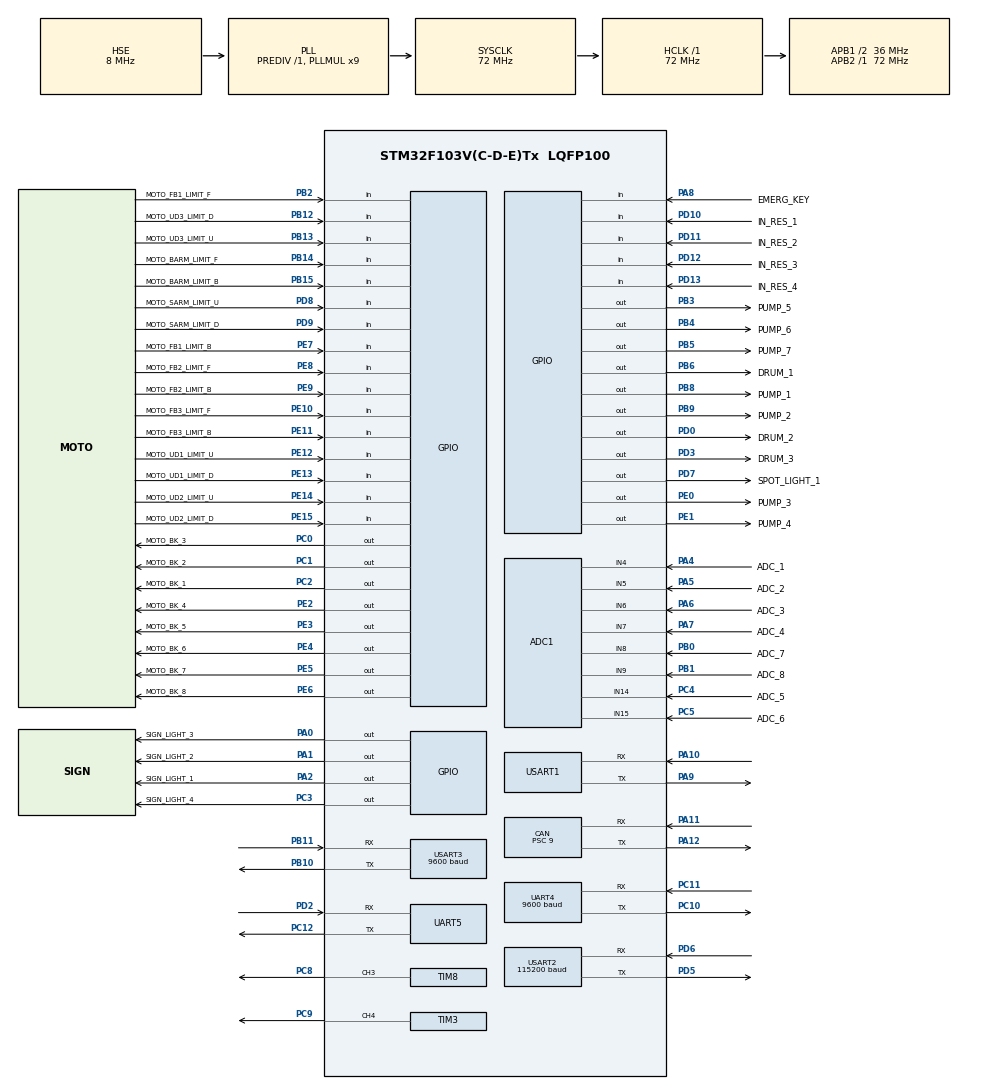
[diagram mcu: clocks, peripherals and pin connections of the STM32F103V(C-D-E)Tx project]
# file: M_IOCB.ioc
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ADC1.Channel-0\#ChannelRegularConversion=ADC_CHANNEL_4
ADC1.Channel-1\#ChannelRegularConversion=ADC_CHANNEL_5
ADC1.Channel-2\#ChannelRegularConversion=ADC_CHANNEL_6
ADC1.Channel-3\#ChannelRegularConversion=ADC_CHANNEL_7
ADC1.Channel-4\#ChannelRegularConversion=ADC_CHANNEL_14
ADC1.Channel-5\#ChannelRegularConversion=ADC_CHANNEL_15
ADC1.Channel-6\#ChannelRegularConversion=ADC_CHANNEL_8
ADC1.Channel-7\#ChannelRegularConversion=ADC_CHANNEL_9
ADC1.Channel-8\#ChannelRegularConversion=ADC_CHANNEL_VREFINT
ADC1.Channel-9\#ChannelRegularConversion=ADC_CHANNEL_TEMPSENSOR
ADC1.ContinuousConvMode=ENABLE
ADC1.DiscontinuousConvMode=DISABLE
ADC1.NbrOfConversion=10
ADC1.NbrOfConversionFlag=1
ADC1.Rank-0\#ChannelRegularConversion=1
ADC1.Rank-1\#ChannelRegularConversion=2
ADC1.Rank-2\#ChannelRegularConversion=3
ADC1.Rank-3\#ChannelRegularConversion=4
ADC1.Rank-4\#ChannelRegularConversion=5
ADC1.Rank-5\#ChannelRegularConversion=6
ADC1.Rank-6\#ChannelRegularConversion=7
ADC1.Rank-7\#ChannelRegularConversion=8
ADC1.Rank-8\#ChannelRegularConversion=9
ADC1.Rank-9\#ChannelRegularConversion=10
ADC1.SamplingTime-0\#ChannelRegularConversion=ADC_SAMPLETIME_1CYCLE_5
ADC1.SamplingTime-1\#ChannelRegularConversion=ADC_SAMPLETIME_1CYCLE_5
ADC1.SamplingTime-2\#ChannelRegularConversion=ADC_SAMPLETIME_1CYCLE_5
ADC1.SamplingTime-3\#ChannelRegularConversion=ADC_SAMPLETIME_1CYCLE_5
ADC1.SamplingTime-4\#ChannelRegularConversion=ADC_SAMPLETIME_1CYCLE_5
ADC1.SamplingTime-5\#ChannelRegularConversion=ADC_SAMPLETIME_1CYCLE_5
ADC1.SamplingTime-6\#ChannelRegularConversion=ADC_SAMPLETIME_1CYCLE_5
ADC1.SamplingTime-7\#ChannelRegularConversion=ADC_SAMPLETIME_1CYCLE_5
ADC1.SamplingTime-8\#ChannelRegularConversion=ADC_SAMPLETIME_1CYCLE_5
ADC1.SamplingTime-9\#ChannelRegularConversion=ADC_SAMPLETIME_1CYCLE_5
ADC1.master=1
CAN.BS1=CAN_BS1_5TQ
CAN.BS2=CAN_BS2_2TQ
CAN.CalculateBaudRate=500000
CAN.CalculateTimeBit=2000
CAN.CalculateTimeQuantum=250.0
CAN.Prescaler=9
CAN.SJW=CAN_SJW_1TQ
Dma.ADC1.2.Direction=DMA_PERIPH_TO_MEMORY
Dma.ADC1.2.Instance=DMA1_Channel1
Dma.ADC1.2.MemDataAlignment=DMA_MDATAALIGN_HALFWORD
Dma.ADC1.2.MemInc=DMA_MINC_ENABLE
Dma.ADC1.2.Mode=DMA_CIRCULAR
Dma.ADC1.2.PeriphDataAlignment=DMA_PDATAALIGN_HALFWORD
Dma.ADC1.2.PeriphInc=DMA_PINC_DISABLE
Dma.ADC1.2.Priority=DMA_PRIORITY_LOW
Dma.Request0=UART4_RX
Dma.Request1=USART1_RX
Dma.Request2=ADC1
Dma.Request3=TIM3_CH4/UP
Dma.Request4=TIM8_CH3/UP
Dma.TIM3_CH4/UP.3.Direction=DMA_MEMORY_TO_PERIPH
Dma.TIM3_CH4/UP.3.Instance=DMA1_Channel3
Dma.TIM3_CH4/UP.3.MemDataAlignment=DMA_MDATAALIGN_WORD
Dma.TIM3_CH4/UP.3.MemInc=DMA_MINC_ENABLE
Dma.TIM3_CH4/UP.3.Mode=DMA_NORMAL
Dma.TIM3_CH4/UP.3.PeriphDataAlignment=DMA_PDATAALIGN_WORD
Dma.TIM3_CH4/UP.3.PeriphInc=DMA_PINC_DISABLE
Dma.TIM3_CH4/UP.3.Priority=DMA_PRIORITY_LOW
Dma.TIM8_CH3/UP.4.Direction=DMA_PERIPH_TO_MEMORY
Dma.TIM8_CH3/UP.4.Instance=DMA2_Channel1
Dma.TIM8_CH3/UP.4.MemDataAlignment=DMA_MDATAALIGN_WORD
Dma.TIM8_CH3/UP.4.MemInc=DMA_MINC_ENABLE
Dma.TIM8_CH3/UP.4.Mode=DMA_NORMAL
Dma.TIM8_CH3/UP.4.PeriphDataAlignment=DMA_PDATAALIGN_WORD
Dma.TIM8_CH3/UP.4.PeriphInc=DMA_PINC_DISABLE
Dma.TIM8_CH3/UP.4.Priority=DMA_PRIORITY_LOW
Dma.UART4_RX.0.Direction=DMA_PERIPH_TO_MEMORY
Dma.UART4_RX.0.Instance=DMA2_Channel3
Dma.UART4_RX.0.MemDataAlignment=DMA_MDATAALIGN_BYTE
Dma.UART4_RX.0.MemInc=DMA_MINC_ENABLE
Dma.UART4_RX.0.Mode=DMA_NORMAL
Dma.UART4_RX.0.PeriphDataAlignment=DMA_PDATAALIGN_BYTE
Dma.UART4_RX.0.PeriphInc=DMA_PINC_DISABLE
Dma.UART4_RX.0.Priority=DMA_PRIORITY_LOW
Dma.USART1_RX.1.Direction=DMA_PERIPH_TO_MEMORY
Dma.USART1_RX.1.Instance=DMA1_Channel5
Dma.USART1_RX.1.MemDataAlignment=DMA_MDATAALIGN_BYTE
Dma.USART1_RX.1.MemInc=DMA_MINC_ENABLE
Dma.USART1_RX.1.Mode=DMA_NORMAL
Dma.USART1_RX.1.PeriphDataAlignment=DMA_PDATAALIGN_BYTE
Dma.USART1_RX.1.PeriphInc=DMA_PINC_DISABLE
Dma.USART1_RX.1.Priority=DMA_PRIORITY_LOW
FREERTOS.INCLUDE_uxTaskGetStackHighWaterMark=1
FREERTOS.Tasks01=defaultTask,0,300,StartDefaultTask,Default,NULL,Dynamic,NULL,NULL
FREERTOS.configGENERATE_RUN_TIME_STATS=0
FREERTOS.configTOTAL_HEAP_SIZE=30000
FREERTOS.configUSE_STATS_FORMATTING_FUNCTIONS=1
FREERTOS.configUSE_TRACE_FACILITY=1
Mcu.Family=STM32F1
Mcu.Name=STM32F103V(C-D-E)Tx
Mcu.Package=LQFP100
NVIC.CAN1_RX1_IRQn=true\:5\:0\:false\:false\:true\:true\:true\:true\:true
NVIC.CAN1_SCE_IRQn=true\:5\:0\:false\:false\:true\:true\:true\:true\:true
NVIC.DMA1_Channel1_IRQn=true\:5\:0\:false\:false\:true\:true\:true\:true\:true
NVIC.DMA1_Channel3_IRQn=true\:5\:0\:false\:false\:true\:true\:true\:true\:true
NVIC.DMA1_Channel5_IRQn=true\:5\:0\:false\:false\:true\:true\:true\:true\:true
NVIC.DMA2_Channel3_IRQn=true\:5\:0\:false\:false\:true\:true\:true\:true\:true
NVIC.PriorityGroup=NVIC_PRIORITYGROUP_4
NVIC.TIM7_IRQn=true\:15\:0\:false\:false\:true\:false\:false\:true\:true
NVIC.TimeBase=TIM7_IRQn
NVIC.TimeBaseIP=TIM7
NVIC.UART4_IRQn=true\:5\:0\:false\:false\:true\:true\:true\:true\:true
NVIC.UART5_IRQn=true\:5\:0\:false\:false\:true\:true\:true\:true\:true
NVIC.USART1_IRQn=true\:5\:0\:true\:false\:true\:true\:true\:true\:true
NVIC.USART2_IRQn=true\:5\:0\:false\:false\:true\:true\:true\:true\:true
NVIC.USART3_IRQn=true\:5\:0\:false\:false\:true\:true\:true\:true\:true
NVIC.USB_HP_CAN1_TX_IRQn=true\:5\:0\:false\:false\:true\:true\:true\:true\:true
NVIC.USB_LP_CAN1_RX0_IRQn=true\:5\:0\:false\:false\:true\:true\:true\:true\:true
OSC_IN.Mode=HSE-External-Oscillator
OSC_IN.Signal=RCC_OSC_IN
OSC_OUT.Mode=HSE-External-Oscillator
OSC_OUT.Signal=RCC_OSC_OUT
PA0-WKUP.GPIO_Label=SIGN_LIGHT_3
PA0-WKUP.GPIO_PuPd=GPIO_NOPULL
PA0-WKUP.Signal=GPIO_Output
PA1.GPIO_Label=SIGN_LIGHT_2
PA1.GPIO_PuPd=GPIO_NOPULL
PA1.Signal=GPIO_Output
PA10.Mode=Asynchronous
PA10.Signal=USART1_RX
PA11.Mode=CAN_Activate
PA11.Signal=CAN_RX
PA12.Mode=CAN_Activate
PA12.Signal=CAN_TX
PA13.Mode=Serial_Wire
PA13.Signal=SYS_JTMS-SWDIO
PA14.Mode=Serial_Wire
PA14.Signal=SYS_JTCK-SWCLK
PA2.GPIO_Label=SIGN_LIGHT_1
PA2.GPIO_PuPd=GPIO_NOPULL
PA2.Signal=GPIO_Output
PA4.GPIO_Label=ADC_1
PA4.Signal=ADCx_IN4
PA5.GPIO_Label=ADC_2
PA5.Signal=ADCx_IN5
PA6.GPIO_Label=ADC_3
PA6.Signal=ADCx_IN6
PA7.GPIO_Label=ADC_4
PA7.Signal=ADCx_IN7
PA8.GPIO_Label=EMERG_KEY
PA8.GPIO_PuPd=GPIO_PULLUP
PA8.Signal=GPIO_Input
PA9.Mode=Asynchronous
PA9.Signal=USART1_TX
PB0.GPIO_Label=ADC_7
PB0.Signal=ADCx_IN8
PB1.GPIO_Label=ADC_8
PB1.Signal=ADCx_IN9
PB10.Mode=Asynchronous
PB10.Signal=USART3_TX
PB11.Mode=Asynchronous
PB11.Signal=USART3_RX
PB12.GPIO_Label=MOTO_UD3_LIMIT_D
PB12.GPIO_PuPd=GPIO_PULLUP
PB12.Signal=GPIO_Input
PB13.GPIO_Label=MOTO_UD3_LIMIT_U
PB13.GPIO_PuPd=GPIO_PULLUP
PB13.Signal=GPIO_Input
PB14.GPIO_Label=MOTO_BARM_LIMIT_F
PB14.GPIO_PuPd=GPIO_PULLUP
PB14.Signal=GPIO_Input
PB15.GPIO_Label=MOTO_BARM_LIMIT_B
PB15.GPIO_PuPd=GPIO_PULLUP
PB15.Signal=GPIO_Input
PB2.GPIO_Label=MOTO_FB1_LIMIT_F
PB2.GPIO_PuPd=GPIO_PULLUP
PB2.Signal=GPIO_Input
PB3.GPIO_Label=PUMP_5
PB3.GPIO_Speed=GPIO_SPEED_FREQ_LOW
PB3.PinState=GPIO_PIN_RESET
PB3.Signal=GPIO_Output
PB4.GPIO_Label=PUMP_6
PB4.GPIO_Speed=GPIO_SPEED_FREQ_LOW
PB4.PinState=GPIO_PIN_RESET
PB4.Signal=GPIO_Output
PB5.GPIO_Label=PUMP_7
PB5.PinState=GPIO_PIN_RESET
PB5.Signal=GPIO_Output
PB6.GPIO_Label=DRUM_1
PB6.Signal=GPIO_Output
PB8.GPIO_Label=PUMP_1
PB8.GPIO_PuPd=GPIO_NOPULL
PB8.Signal=GPIO_Output
PB9.GPIO_Label=PUMP_2
PB9.GPIO_PuPd=GPIO_NOPULL
PB9.Signal=GPIO_Output
PC0.GPIO_Label=MOTO_BK_3
PC0.GPIO_PuPd=GPIO_NOPULL
PC0.Signal=GPIO_Output
PC1.GPIO_Label=MOTO_BK_2
PC1.GPIO_PuPd=GPIO_NOPULL
PC1.Signal=GPIO_Output
PC10.Mode=Asynchronous
PC10.Signal=UART4_TX
PC11.Mode=Asynchronous
PC11.Signal=UART4_RX
PC12.Mode=Asynchronous
PC12.Signal=UART5_TX
PC2.GPIO_Label=MOTO_BK_1
PC2.GPIO_PuPd=GPIO_NOPULL
PC2.Signal=GPIO_Output
PC3.GPIO_Label=SIGN_LIGHT_4
PC3.GPIO_PuPd=GPIO_NOPULL
PC3.Signal=GPIO_Output
PC4.GPIO_Label=ADC_5
PC4.Signal=ADCx_IN14
PC5.GPIO_Label=ADC_6
PC5.Signal=ADCx_IN15
PC8.Signal=S_TIM8_CH3
PC9.Signal=S_TIM3_CH4
PD0.GPIO_Label=DRUM_2
PD0.Signal=GPIO_Output
PD10.GPIO_Label=IN_RES_1
PD10.GPIO_PuPd=GPIO_PULLUP
PD10.Signal=GPIO_Input
PD11.GPIO_Label=IN_RES_2
PD11.GPIO_PuPd=GPIO_PULLUP
PD11.Signal=GPIO_Input
PD12.GPIO_Label=IN_RES_3
PD12.GPIO_PuPd=GPIO_PULLUP
PD12.Signal=GPIO_Input
PD13.GPIO_Label=IN_RES_4
PD13.GPIO_PuPd=GPIO_PULLUP
PD13.Signal=GPIO_Input
PD2.Mode=Asynchronous
PD2.Signal=UART5_RX
PD3.GPIO_Label=DRUM_3
PD3.Signal=GPIO_Output
PD5.Mode=Asynchronous
PD5.Signal=USART2_TX
PD6.Mode=Asynchronous
PD6.Signal=USART2_RX
PD7.GPIO_Label=SPOT_LIGHT_1
PD7.Signal=GPIO_Output
PD8.GPIO_Label=MOTO_SARM_LIMIT_U
PD8.GPIO_PuPd=GPIO_PULLUP
PD8.Signal=GPIO_Input
PD9.GPIO_Label=MOTO_SARM_LIMIT_D
PD9.GPIO_PuPd=GPIO_PULLUP
PD9.Signal=GPIO_Input
PE0.GPIO_Label=PUMP_3
PE0.GPIO_PuPd=GPIO_NOPULL
PE0.Signal=GPIO_Output
PE1.GPIO_Label=PUMP_4
PE1.GPIO_PuPd=GPIO_NOPULL
PE1.Signal=GPIO_Output
PE10.GPIO_Label=MOTO_FB3_LIMIT_F
PE10.GPIO_PuPd=GPIO_PULLUP
PE10.Signal=GPIO_Input
PE11.GPIO_Label=MOTO_FB3_LIMIT_B
PE11.GPIO_PuPd=GPIO_PULLUP
PE11.Signal=GPIO_Input
PE12.GPIO_Label=MOTO_UD1_LIMIT_U
PE12.GPIO_PuPd=GPIO_PULLUP
PE12.Signal=GPIO_Input
PE13.GPIO_Label=MOTO_UD1_LIMIT_D
PE13.GPIO_PuPd=GPIO_PULLUP
PE13.Signal=GPIO_Input
PE14.GPIO_Label=MOTO_UD2_LIMIT_U
PE14.GPIO_PuPd=GPIO_PULLUP
PE14.Signal=GPIO_Input
PE15.GPIO_Label=MOTO_UD2_LIMIT_D
PE15.GPIO_PuPd=GPIO_PULLUP
PE15.Signal=GPIO_Input
PE2.GPIO_Label=MOTO_BK_4
PE2.GPIO_PuPd=GPIO_NOPULL
PE2.Signal=GPIO_Output
PE3.GPIO_Label=MOTO_BK_5
PE3.GPIO_PuPd=GPIO_NOPULL
PE3.Signal=GPIO_Output
PE4.GPIO_Label=MOTO_BK_6
PE4.GPIO_PuPd=GPIO_NOPULL
PE4.Signal=GPIO_Output
PE5.GPIO_Label=MOTO_BK_7
PE5.GPIO_PuPd=GPIO_NOPULL
PE5.Signal=GPIO_Output
PE6.GPIO_Label=MOTO_BK_8
PE6.GPIO_PuPd=GPIO_NOPULL
PE6.Signal=GPIO_Output
PE7.GPIO_Label=MOTO_FB1_LIMIT_B
PE7.GPIO_PuPd=GPIO_PULLUP
PE7.Signal=GPIO_Input
PE8.GPIO_Label=MOTO_FB2_LIMIT_F
PE8.GPIO_PuPd=GPIO_PULLUP
PE8.Signal=GPIO_Input
PE9.GPIO_Label=MOTO_FB2_LIMIT_B
PE9.GPIO_PuPd=GPIO_PULLUP
PE9.Signal=GPIO_Input
ProjectManager.HeapSize=0x200
ProjectManager.StackSize=0x400
ProjectManager.TargetToolchain=MDK-ARM V5.32
RCC.ADCPresc=RCC_ADCPCLK2_DIV6
RCC.AHBFreq_Value=72000000
RCC.APB1CLKDivider=RCC_HCLK_DIV2
RCC.APB1Freq_Value=36000000
RCC.APB1TimFreq_Value=72000000
RCC.APB2Freq_Value=72000000
RCC.APB2TimFreq_Value=72000000
RCC.HCLKFreq_Value=72000000
RCC.PLLMUL=RCC_PLL_MUL9
RCC.PLLSourceVirtual=RCC_PLLSOURCE_HSE
RCC.SYSCLKFreq_VALUE=72000000
RCC.SYSCLKSource=RCC_SYSCLKSOURCE_PLLCLK
RCC.USBFreq_Value=72000000
RTC.Format=RTC_FORMAT_BIN
SH.ADCx_IN14.0=ADC1_IN14,IN14
SH.ADCx_IN15.0=ADC1_IN15,IN15
SH.ADCx_IN4.0=ADC1_IN4,IN4
SH.ADCx_IN5.0=ADC1_IN5,IN5
SH.ADCx_IN6.0=ADC1_IN6,IN6
SH.ADCx_IN7.0=ADC1_IN7,IN7
SH.ADCx_IN8.0=ADC1_IN8,IN8
SH.ADCx_IN9.0=ADC1_IN9,IN9
SH.S_TIM3_CH4.0=TIM3_CH4,PWM Generation4 CH4
SH.S_TIM8_CH3.0=TIM8_CH3,PWM Generation3 CH3
TIM3.Channel-PWM\ Generation4\ CH4=TIM_CHANNEL_4
TIM3.Period=89
TIM8.Channel-PWM\ Generation3\ CH3=TIM_CHANNEL_3
TIM8.Period=89
UART4.BaudRate=9600
UART4.VirtualMode=Asynchronous
UART5.VirtualMode=Asynchronous
USART1.VirtualMode=VM_ASYNC
USART2.BaudRate=115200
USART2.VirtualMode=VM_ASYNC
USART3.BaudRate=9600
USART3.VirtualMode=VM_ASYNC
VP_ADC1_TempSens_Input.Mode=IN-TempSens
VP_ADC1_Vref_Input.Mode=IN-Vrefint
VP_FREERTOS_VS_CMSIS_V1.Mode=CMSIS_V1
VP_RTC_VS_RTC_Activate.Mode=RTC_Enabled
VP_RTC_VS_RTC_Calendar.Mode=RTC_Calendar
VP_SYS_VS_tim7.Mode=TIM7
VP_TIM3_VS_ClockSourceINT.Mode=Internal
board=custom

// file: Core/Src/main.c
/* USER CODE BEGIN Header */
/**
 ******************************************************************************
 * @file           : main.c
 * @brief          : Main program body
 ******************************************************************************
 * @attention
 *
 * Copyright (c) 2023 STMicroelectronics.
 * All rights reserved.
 *
 * This software is licensed under terms that can be found in the LICENSE file
 * in the root directory of this software component.
 * If no LICENSE file comes with this software, it is provided AS-IS.
 *
 ******************************************************************************
 */
/* USER CODE END Header */
#include "main.h"
#include "cmsis_os.h"
#include "adc.h"
#include "can.h"
#include "dma.h"
#include "rtc.h"
#include "tim.h"
#include "usart.h"
#include "gpio.h"

/* USER CODE BEGIN Includes */
#include <stdio.h>
/* USER CODE END Includes */

void SystemClock_Config(void);
void MX_FREERTOS_Init(void);

int main(void)
{

  /* MCU Configuration--------------------------------------------------------*/

  /* Reset of all peripherals, Initializes the Flash interface and the Systick. */
  HAL_Init();

  /* Configure the system clock */
  SystemClock_Config();

  /* Initialize all configured peripherals */
  MX_GPIO_Init();
  MX_DMA_Init();
  MX_RTC_Init();
  MX_USART1_UART_Init();
  MX_UART4_Init();
  MX_UART5_Init();
  MX_USART2_UART_Init();
  MX_USART3_UART_Init();
  MX_ADC1_Init();
  MX_CAN_Init();
  MX_TIM3_Init();
  MX_TIM8_Init();

  /* Call init function for freertos objects (in freertos.c) */
  MX_FREERTOS_Init();

  /* Start scheduler */
  osKernelStart();

  /* We should never get here as control is now taken by the scheduler */
  /* Infinite loop */
  while (1)
  {

  }
}

void SystemClock_Config(void)
{
  RCC_OscInitTypeDef RCC_OscInitStruct = {0};
  RCC_ClkInitTypeDef RCC_ClkInitStruct = {0};
  RCC_PeriphCLKInitTypeDef PeriphClkInit = {0};

  /** Initializes the RCC Oscillators according to the specified parameters
  * in the RCC_OscInitTypeDef structure.
  */
  RCC_OscInitStruct.OscillatorType = RCC_OSCILLATORTYPE_LSI|RCC_OSCILLATORTYPE_HSE;
  RCC_OscInitStruct.HSEState = RCC_HSE_ON;
  RCC_OscInitStruct.HSEPredivValue = RCC_HSE_PREDIV_DIV1;
  RCC_OscInitStruct.HSIState = RCC_HSI_ON;
  RCC_OscInitStruct.LSIState = RCC_LSI_ON;
  RCC_OscInitStruct.PLL.PLLState = RCC_PLL_ON;
  RCC_OscInitStruct.PLL.PLLSource = RCC_PLLSOURCE_HSE;
  RCC_OscInitStruct.PLL.PLLMUL = RCC_PLL_MUL9;
  if (HAL_RCC_OscConfig(&RCC_OscInitStruct) != HAL_OK)
  {
    Error_Handler();
  }

  /** Initializes the CPU, AHB and APB buses clocks
  */
  RCC_ClkInitStruct.ClockType = RCC_CLOCKTYPE_HCLK|RCC_CLOCKTYPE_SYSCLK
                              |RCC_CLOCKTYPE_PCLK1|RCC_CLOCKTYPE_PCLK2;
  RCC_ClkInitStruct.SYSCLKSource = RCC_SYSCLKSOURCE_PLLCLK;
  RCC_ClkInitStruct.AHBCLKDivider = RCC_SYSCLK_DIV1;
  RCC_ClkInitStruct.APB1CLKDivider = RCC_HCLK_DIV2;
  RCC_ClkInitStruct.APB2CLKDivider = RCC_HCLK_DIV1;

  if (HAL_RCC_ClockConfig(&RCC_ClkInitStruct, FLASH_LATENCY_2) != HAL_OK)
  {
    Error_Handler();
  }
  PeriphClkInit.PeriphClockSelection = RCC_PERIPHCLK_RTC|RCC_PERIPHCLK_ADC;
  PeriphClkInit.RTCClockSelection = RCC_RTCCLKSOURCE_LSI;
  PeriphClkInit.AdcClockSelection = RCC_ADCPCLK2_DIV6;
  if (HAL_RCCEx_PeriphCLKConfig(&PeriphClkInit) != HAL_OK)
  {
    Error_Handler();
  }
}

/* USER CODE BEGIN 4 */
int fputc(int ch, FILE *f)
{
  HAL_UART_Transmit(&huart1, (uint8_t *)&ch, 1, 0xFFFF);
  return ch;
}

/* USER CODE END 4 */

void HAL_TIM_PeriodElapsedCallback(TIM_HandleTypeDef *htim)
{
  if (htim->Instance == TIM7) {
    HAL_IncTick();
  }
}

void Error_Handler(void)
{
  __disable_irq();
  while (1)
  {
  }
}

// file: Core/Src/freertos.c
/* USER CODE BEGIN Header */
/**
 ******************************************************************************
 * File Name          : freertos.c
 * Description        : Code for freertos applications
 ******************************************************************************
 * @attention
 *
 * Copyright (c) 2023 STMicroelectronics.
 * All rights reserved.
 *
 * This software is licensed under terms that can be found in the LICENSE file
 * in the root directory of this software component.
 * If no LICENSE file comes with this software, it is provided AS-IS.
 *
 ******************************************************************************
 */
/* USER CODE END Header */

#include "FreeRTOS.h"
#include "task.h"
#include "main.h"
#include "cmsis_os.h"

/* USER CODE BEGIN Includes */
#include "stdio.h"
#include "motor_drive.h"
#include "can.h"
#include "adc.h"
#include "usart.h"
#include "elog.h"
#include "flashdb.h"
#include "tim.h"
#include "console.h"
#include "ws2812.h"
#include "liquid_level.h"
#include "hcp.h"
#include "brush.h"
#include "flowmeter_hl.h"
// #include "battery.h"
/* USER CODE END Includes */

/* USER CODE BEGIN PD */

TaskHandle_t test_task_handle;
extern TaskHandle_t console_task_handle;
extern TaskHandle_t motor_task_handle;
extern TaskHandle_t rgb_task_handle;
extern TaskHandle_t liquid_level_task_handle;
extern TaskHandle_t hcp_task_handle;
extern TaskHandle_t brush_deamon_task_handle;
extern TaskHandle_t flowmeter_task_handle;
extern TaskHandle_t battery_task_handle;
extern TaskHandle_t accurate_ratio_task_handle;

void test_task(void);

unsigned char u1_rec_buf[100];

// static uint32_t boot_count = 0;
// struct fdb_default_kv default_kv;
// static struct fdb_kvdb kvdb = {0};
// static struct fdb_default_kv_node default_kv_table[] = {
//     {"boot_count", &boot_count, sizeof(boot_count)}, /* int type KV */
// };

unsigned char pb_bat_level = 0;
unsigned char pb_charge_state = 0;
unsigned char pb_rec_buf[5] = {0};
unsigned char pb_rec = 0;
/* USER CODE END PD */

osThreadId defaultTaskHandle;

/* USER CODE BEGIN FunctionPrototypes */
void cs_task_manager_cb(unsigned char *cmd);
void cs_task_HighWaterMark_cb(unsigned char *cmd);
/* USER CODE END FunctionPrototypes */

void StartDefaultTask(void const *argument);

void MX_FREERTOS_Init(void); /* (MISRA C 2004 rule 8.1) */

/* GetIdleTaskMemory prototype (linked to static allocation support) */
void vApplicationGetIdleTaskMemory(StaticTask_t **ppxIdleTaskTCBBuffer, StackType_t **ppxIdleTaskStackBuffer, uint32_t *pulIdleTaskStackSize);

/* USER CODE BEGIN GET_IDLE_TASK_MEMORY */
static StaticTask_t xIdleTaskTCBBuffer;
static StackType_t xIdleStack[configMINIMAL_STACK_SIZE];

void vApplicationGetIdleTaskMemory(StaticTask_t **ppxIdleTaskTCBBuffer, StackType_t **ppxIdleTaskStackBuffer, uint32_t *pulIdleTaskStackSize)
{
  *ppxIdleTaskTCBBuffer = &xIdleTaskTCBBuffer;
  *ppxIdleTaskStackBuffer = &xIdleStack[0];
  *pulIdleTaskStackSize = configMINIMAL_STACK_SIZE;
  /* place for user code */
}
/* USER CODE END GET_IDLE_TASK_MEMORY */

void MX_FREERTOS_Init(void)
{
  /* USER CODE BEGIN Init */
  // default_kv.kvs = default_kv_table;
  // default_kv.num = sizeof(default_kv_table) / sizeof(default_kv_table[0]);
  // fdb_kvdb_init(&kvdb, "NVS", "fdb", &default_kv, NULL);
  elog_my_init();
  cs_init();
  HAL_UART_Receive_IT(&huart5, &pb_rec, 1);
  // cs_recv_start();
  /* USER CODE END Init */

  /* Create the thread(s) */
  /* definition and creation of defaultTask */
  osThreadDef(defaultTask, StartDefaultTask, osPriorityNormal, 0, 300);
  defaultTaskHandle = osThreadCreate(osThread(defaultTask), NULL);

  /* USER CODE BEGIN RTOS_THREADS */
  /* add threads, ... */
  xTaskCreate((TaskFunction_t)console_task, "console_task", 600, NULL, 0, &console_task_handle);
  xTaskCreate((TaskFunction_t)hcp_task, "hcp task", 600, NULL, 5, &hcp_task_handle);
  // xTaskCreate((TaskFunction_t)test_task, "test_task", 400, NULL, 0, &test_task_handle);
  xTaskCreate((TaskFunction_t)motor_task, "motor_task", 400, NULL, 0, &motor_task_handle);
  // xTaskCreate((TaskFunction_t)rgb_task, "rgb_task", 100, NULL, 2, &rgb_task_handle);
  xTaskCreate((TaskFunction_t)liquid_level_task, "liquid level task", 100, NULL, 0, &liquid_level_task_handle);
  xTaskCreate((TaskFunction_t)brush_deamon_task, "brush deamon task", 400, NULL, 4, &brush_deamon_task_handle);
  xTaskCreate((TaskFunction_t)flowmeter_task, "flowmeter task", 200, NULL, 1, &flowmeter_task_handle);
  // xTaskCreate((TaskFunction_t)battery_task, "battery task", 200, NULL, 1, &battery_task_handle);
  xTaskCreate((TaskFunction_t)accurate_ratio_task, "accurate ratio task", 200, NULL, 1, &accurate_ratio_task_handle);
  /* USER CODE END RTOS_THREADS */
}

void StartDefaultTask(void const *argument)
{
  /* USER CODE BEGIN StartDefaultTask */
  /* Infinite loop */

  // struct fdb_blob blob;
  // int boot_count = 0;

  // printf("\r==================== kvdb_basic_sample ====================\r\n");
  // { /* GET the KV value */
  //   /* get the "boot_count" KV value */
  //   fdb_kv_get_blob(&kvdb, "boot_count", fdb_blob_make(&blob, &boot_count, sizeof(boot_count)));
  //   /* the blob.saved.len is more than 0 when get the value successful */
  //   if (blob.saved.len > 0)
  //   {
  //     printf("get the 'boot_count' value is %d\r\n", boot_count);
  //   }
  //   else
  //   {
  //     printf("get the 'boot_count' failed\r\n");
  //   }
  // }
  // { /* CHANGE the KV value */
  //   /* increase the boot count */
  //   boot_count++;
  //   /* change the "boot_count" KV's value */
  //   fdb_kv_set_blob(&kvdb, "boot_count", fdb_blob_make(&blob, &boot_count, sizeof(boot_count)));
  //   // printf("set the 'boot_count' value to %d\n", boot_count);
  // }
  // printf("===========================================================\r\n");

  cs_reg_fun("info", cs_task_HighWaterMark_cb);
  cs_reg_fun("sys", cs_task_manager_cb);
  // MOTOR_BK_ON[0]();
  // MOTOR_BK_ON[1]();
  // MOTOR_BK_ON[2]();
  // MOTOR_BK_ON[3]();
  // MOTOR_BK_ON[4]();
  // MOTOR_BK_ON[5]();
  // MOTOR_BK_ON[6]();
  // MOTOR_BK_ON[7]();

  // vTaskDelete(NULL);
  // char bat = 0;
  vTaskDelay(6000 / portTICK_RATE_MS);
  for (;;)
  {
    // bat_get_power(&bat);
    // printf("%d", bat);
    osDelay(200);

    // elog_i("speed", "%d#%ld", motor_read_speed(MOTOR_STATION[MOTOR_UD_2]), motor_read_position(MOTOR_STATION[MOTOR_UD_2]));
    // printf("%d-%d-%d-%d-%d-%d-%d-%d-%d-%d-%d-%d-%d-%d-%d-%d\r\n",
    //    HAL_GPIO_ReadPin(MOTO_FB1_LIMIT_F_GPIO_Port, MOTO_FB1_LIMIT_F_Pin),
    //    HAL_GPIO_ReadPin(MOTO_FB1_LIMIT_B_GPIO_Port, MOTO_FB1_LIMIT_B_Pin),
    //    HAL_GPIO_ReadPin(MOTO_FB2_LIMIT_F_GPIO_Port, MOTO_FB2_LIMIT_F_Pin),
    //    HAL_GPIO_ReadPin(MOTO_FB2_LIMIT_B_GPIO_Port, MOTO_FB2_LIMIT_B_Pin),
    //    HAL_GPIO_ReadPin(MOTO_FB3_LIMIT_F_GPIO_Port, MOTO_FB3_LIMIT_F_Pin),
    //    HAL_GPIO_ReadPin(MOTO_FB3_LIMIT_B_GPIO_Port, MOTO_FB3_LIMIT_B_Pin),
    //    HAL_GPIO_ReadPin(MOTO_UD1_LIMIT_U_GPIO_Port, MOTO_UD1_LIMIT_U_Pin),
    //    HAL_GPIO_ReadPin(MOTO_UD1_LIMIT_D_GPIO_Port, MOTO_UD1_LIMIT_D_Pin),
    //    HAL_GPIO_ReadPin(MOTO_UD2_LIMIT_U_GPIO_Port, MOTO_UD2_LIMIT_U_Pin),
    //    HAL_GPIO_ReadPin(MOTO_UD2_LIMIT_D_GPIO_Port, MOTO_UD2_LIMIT_D_Pin),
    //    HAL_GPIO_ReadPin(MOTO_UD3_LIMIT_D_GPIO_Port, MOTO_UD3_LIMIT_D_Pin),
    //    HAL_GPIO_ReadPin(MOTO_UD3_LIMIT_U_GPIO_Port, MOTO_UD3_LIMIT_U_Pin),
    //    HAL_GPIO_ReadPin(MOTO_BARM_LIMIT_F_GPIO_Port, MOTO_BARM_LIMIT_F_Pin),
    //    HAL_GPIO_ReadPin(MOTO_BARM_LIMIT_B_GPIO_Port, MOTO_BARM_LIMIT_B_Pin),
    //    HAL_GPIO_ReadPin(MOTO_SARM_LIMIT_U_GPIO_Port, MOTO_SARM_LIMIT_U_Pin),
    //    HAL_GPIO_ReadPin(MOTO_SARM_LIMIT_D_GPIO_Port, MOTO_SARM_LIMIT_D_Pin));

    // HAL_GPIO_TogglePin(OU_RES_4_GPIO_Port, OU_RES_4_Pin);
    // HAL_GPIO_TogglePin(OU_RES_5_GPIO_Port, OU_RES_5_Pin);
  }
  /* USER CODE END StartDefaultTask */
}

/* USER CODE BEGIN Application */

void test_task()
{

  // char send_buf[25];
  // unsigned int liquid_level_1 = 0;
  // unsigned int liquid_level_2 = 0;
  // unsigned int liquid_level_3 = 0;
  // unsigned int liquid_level_4 = 0;
  // rgb_test_fun();
  // HAL_TIM_PWM_Start(&htim3,TIM_CHANNEL_4);
  // __HAL_TIM_SetCompare(&htim3, TIM_CHANNEL_4, 20);

  while (1)
  {
    // get_liquid_level(&liquid_level_1, &liquid_level_2, &liquid_level_3, &liquid_level_4);
    // sprintf(send_buf, "%d,%d,%d,%d\r\n", liquid_level_1, liquid_level_2, liquid_level_3, liquid_level_4);
    // printf("%s", send_buf);

    // HAL_GPIO_TogglePin(SIGN_LIGHT_1_GPIO_Port, SIGN_LIGHT_1_Pin);
    // vTaskDelay(50 / portTICK_RATE_MS);
    // HAL_GPIO_TogglePin(SIGN_LIGHT_2_GPIO_Port, SIGN_LIGHT_2_Pin);
    // vTaskDelay(50 / portTICK_RATE_MS);
    // HAL_GPIO_TogglePin(SIGN_LIGHT_3_GPIO_Port, SIGN_LIGHT_3_Pin);
    // vTaskDelay(50 / portTICK_RATE_MS);
    // HAL_GPIO_TogglePin(SIGN_LIGHT_4_GPIO_Port, SIGN_LIGHT_4_Pin);
    // vTaskDelay(50 / portTICK_RATE_MS);
    // HAL_GPIO_TogglePin(MOTO_BK_1_GPIO_Port, MOTO_BK_1_Pin);
    // vTaskDelay(50 / portTICK_RATE_MS);
    // HAL_GPIO_TogglePin(MOTO_BK_2_GPIO_Port, MOTO_BK_2_Pin);
    // vTaskDelay(50 / portTICK_RATE_MS);
    // HAL_GPIO_TogglePin(MOTO_BK_3_GPIO_Port, MOTO_BK_3_Pin);
    // vTaskDelay(50 / portTICK_RATE_MS);
    // HAL_GPIO_TogglePin(MOTO_BK_4_GPIO_Port, MOTO_BK_4_Pin);
    // vTaskDelay(50 / portTICK_RATE_MS);
    // HAL_GPIO_TogglePin(MOTO_BK_5_GPIO_Port, MOTO_BK_5_Pin);
    // vTaskDelay(50 / portTICK_RATE_MS);
    // HAL_GPIO_TogglePin(MOTO_BK_6_GPIO_Port, MOTO_BK_6_Pin);
    // vTaskDelay(50 / portTICK_RATE_MS);
    // HAL_GPIO_TogglePin(MOTO_BK_7_GPIO_Port, MOTO_BK_7_Pin);
    // vTaskDelay(50 / portTICK_RATE_MS);
    // HAL_GPIO_TogglePin(MOTO_BK_8_GPIO_Port, MOTO_BK_8_Pin);

    // vTaskDelay(50 / portTICK_RATE_MS);
    // HAL_GPIO_TogglePin(PUMP_1_GPIO_Port, PUMP_1_Pin);
    // vTaskDelay(50 / portTICK_RATE_MS);
    // HAL_GPIO_TogglePin(PUMP_2_GPIO_Port, PUMP_2_Pin);
    // vTaskDelay(50 / portTICK_RATE_MS);
    // HAL_GPIO_TogglePin(PUMP_3_GPIO_Port, PUMP_3_Pin);
    // vTaskDelay(50 / portTICK_RATE_MS);
    // HAL_GPIO_TogglePin(PUMP_4_GPIO_Port, PUMP_4_Pin);
    // vTaskDelay(50 / portTICK_RATE_MS);

    // HAL_GPIO_TogglePin(DRUM_1_GPIO_Port, DRUM_1_Pin);
    // vTaskDelay(50 / portTICK_RATE_MS);
    // HAL_GPIO_TogglePin(DRUM_2_GPIO_Port, DRUM_2_Pin);
    // vTaskDelay(50 / portTICK_RATE_MS);
    // HAL_GPIO_TogglePin(DRUM_3_GPIO_Port, DRUM_3_Pin);
    // vTaskDelay(50 / portTICK_RATE_MS);

    // HAL_GPIO_TogglePin(SPOT_LIGHT_1_GPIO_Port, SPOT_LIGHT_1_Pin);
    // vTaskDelay(50 / portTICK_RATE_MS);
    // HAL_GPIO_TogglePin(SPOT_LIGHT_2_GPIO_Port, SPOT_LIGHT_2_Pin);
    // vTaskDelay(50 / portTICK_RATE_MS);

    // HAL_UART_Transmit(&huart2, "hello\r\n", 7, 1000);
    vTaskDelay(500 / portTICK_RATE_MS);
    printf("%d-%d-%d-%d-%d-%d-%d-%d-%d-%d-%d-%d-%d-%d-%d-%d\r\n",
           HAL_GPIO_ReadPin(MOTO_FB1_LIMIT_F_GPIO_Port, MOTO_FB1_LIMIT_F_Pin),
           HAL_GPIO_ReadPin(MOTO_FB1_LIMIT_B_GPIO_Port, MOTO_FB1_LIMIT_B_Pin),
           HAL_GPIO_ReadPin(MOTO_FB2_LIMIT_F_GPIO_Port, MOTO_FB2_LIMIT_F_Pin),
           HAL_GPIO_ReadPin(MOTO_FB2_LIMIT_B_GPIO_Port, MOTO_FB2_LIMIT_B_Pin),
           HAL_GPIO_ReadPin(MOTO_FB3_LIMIT_F_GPIO_Port, MOTO_FB3_LIMIT_F_Pin),
           HAL_GPIO_ReadPin(MOTO_FB3_LIMIT_B_GPIO_Port, MOTO_FB3_LIMIT_B_Pin),
           HAL_GPIO_ReadPin(MOTO_UD1_LIMIT_U_GPIO_Port, MOTO_UD1_LIMIT_U_Pin),
           HAL_GPIO_ReadPin(MOTO_UD1_LIMIT_D_GPIO_Port, MOTO_UD1_LIMIT_D_Pin),
           HAL_GPIO_ReadPin(MOTO_UD2_LIMIT_U_GPIO_Port, MOTO_UD2_LIMIT_U_Pin),
           HAL_GPIO_ReadPin(MOTO_UD2_LIMIT_D_GPIO_Port, MOTO_UD2_LIMIT_D_Pin),
           HAL_GPIO_ReadPin(MOTO_UD3_LIMIT_U_GPIO_Port, MOTO_UD3_LIMIT_U_Pin),
           HAL_GPIO_ReadPin(MOTO_UD3_LIMIT_D_GPIO_Port, MOTO_UD3_LIMIT_D_Pin),
           HAL_GPIO_ReadPin(MOTO_BARM_LIMIT_F_GPIO_Port, MOTO_BARM_LIMIT_F_Pin),
           HAL_GPIO_ReadPin(MOTO_BARM_LIMIT_B_GPIO_Port, MOTO_BARM_LIMIT_B_Pin),
           HAL_GPIO_ReadPin(MOTO_SARM_LIMIT_U_GPIO_Port, MOTO_SARM_LIMIT_U_Pin),
           HAL_GPIO_ReadPin(MOTO_SARM_LIMIT_D_GPIO_Port, MOTO_SARM_LIMIT_D_Pin));
  }
}

void HAL_UARTEx_RxEventCallback(UART_HandleTypeDef *huart, uint16_t Size)
{
  // Log serial port
  if (huart == &huart1)
  {
    cs_recv_callback(Size);
  }
  else if (huart == &huart4)
  {
    fm_recv_callback(Size);
  }
  // 232 serial port of upper computer
  // else if (huart == &huart2)
  // {
  //   hcp_recv_callback(Size);
  // }
  // power
  // else if (huart == &huart3)
  // {
  //   bat_recv_callback(Size);
  // }
}

extern unsigned char hcp_buf[40];
extern unsigned char hcp_rec_s;
void HAL_UART_RxCpltCallback(UART_HandleTypeDef *huart)
{
  static unsigned char pb_rec_buf[5] = {0};
  static unsigned char pb_rec_index = 0;
  static unsigned int hcp_rec_index = 0;

  if (huart == &huart5)
  {
    if (pb_rec == 0x5a)
    {
      pb_rec_index = 0;
    }
    pb_rec_buf[pb_rec_index++] = pb_rec;
    if (pb_rec_index > 3)
    {
      if (pb_rec == 0xa5)
      {
        pb_bat_level = pb_rec_buf[1];
        pb_charge_state = pb_rec_buf[2];
        // printf("%d-%d\r\n", pb_bat_level, pb_charge_state);
      }
      pb_rec_index = 0;
    }
    HAL_UART_Receive_IT(&huart5, &pb_rec, 1);
  }
  else if (huart == &huart2)
  {
    if (hcp_rec_s == 0x5a)
    {
      if (hcp_buf[0] != 0x5a)
      {
        hcp_rec_index = 0;
      }
    }
    hcp_buf[hcp_rec_index++] = hcp_rec_s;
    if (hcp_rec_index > 15)
    {
      hcp_recv_callback(hcp_rec_index);
      hcp_rec_index = 0;
    }
    else
    {
      HAL_UART_Receive_IT(&huart2, &hcp_rec_s, 1);
    }
  }
}

void cs_task_manager_cb(unsigned char *cmd)
{
  unsigned char write_buffer[500];
  vTaskList((char *)&write_buffer);
  printf("taskname      taskstate priority   free num\r\n");
  printf("%s\r\n\r\n\r\n\r\n", write_buffer);
}

void cs_task_HighWaterMark_cb(unsigned char *cmd)
{
  // elog_d("TASK-STATE", "default task      - > %d", (int)uxTaskGetStackHighWaterMark(defaultTaskHandle));
  // elog_d("TASK-STATE", "test task         - > %d", (int)uxTaskGetStackHighWaterMark(test_task_handle));
  elog_d("TASK-STATE", "console task           - > %d", (int)uxTaskGetStackHighWaterMark(console_task_handle));
  elog_d("TASK-STATE", "motor task             - > %d", (int)uxTaskGetStackHighWaterMark(motor_task_handle));
  elog_d("TASK-STATE", "rgb task               - > %d", (int)uxTaskGetStackHighWaterMark(rgb_task_handle));
  elog_d("TASK-STATE", "liquid leval task      - > %d", (int)uxTaskGetStackHighWaterMark(liquid_level_task_handle));
  elog_d("TASK-STATE", "hcp task               - > %d", (int)uxTaskGetStackHighWaterMark(hcp_task_handle));
  elog_d("TASK-STATE", "brush deamon_task      - > %d", (int)uxTaskGetStackHighWaterMark(brush_deamon_task_handle));
  elog_d("TASK-STATE", "flowmeter task         - > %d", (int)uxTaskGetStackHighWaterMark(flowmeter_task_handle));
  // elog_d("TASK-STATE", "battery task           - > %d", (int)uxTaskGetStackHighWaterMark(battery_task_handle));
  elog_d("TASK-STATE", "accurate ratio task    - > %d", (int)uxTaskGetStackHighWaterMark(accurate_ratio_task_handle));
}

/* USER CODE END Application */
